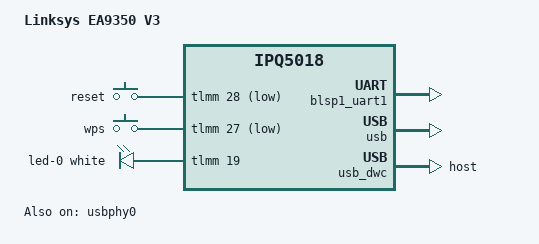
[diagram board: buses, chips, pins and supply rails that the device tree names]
// SPDX-License-Identifier: GPL-2.0+ OR BSD-3-Clause

/dts-v1/;

/*
 * NOTE: The original firmware from Linksys can only boot ARM32 kernels.
 *
 * As of now There seems to be no way to boot ARM64 kernels on those device.
 *
 * However, it is possible to use this device tree by compiling an ARM32 kernel
 * instead. For clarity and build testing this device tree is maintained next
 * to the other IPQ5018 device trees. However, it is actually used through
 * arch/arm/boot/dts/qcom/qcom-ipq5018-linksys-jamaica.dts
 */

#include "ipq5018.dtsi"
#include <dt-bindings/input/input.h>
#include <dt-bindings/leds/common.h>
#include <dt-bindings/gpio/gpio.h>


/ {
	model = "Linksys EA9350 V3";
	compatible = "linksys,jamaica", "qcom,ipq5018";

	aliases {
		serial0 = &blsp1_uart1;
	};

	chosen {
		stdout-path = "serial0:115200n8";
	};

	gpio-keys {
		compatible = "gpio-keys";
		pinctrl-0 = <&button_pins>;
		pinctrl-names = "default";

		button-0 {
			label = "reset";
			linux,code = <KEY_RESTART>;
			gpios = <&tlmm 28 GPIO_ACTIVE_LOW>;
			debounce-interval = <60>;
		};

		button-1 {
			label = "wps";
			linux,code = <KEY_WPS_BUTTON>;
			gpios = <&tlmm 27 GPIO_ACTIVE_LOW>;
			debounce-interval = <60>;
		};
	};

	leds {
		compatible = "gpio-leds";
		pinctrl-0 = <&led_pins>;
		pinctrl-names = "default";

		led-0 {
			color = <LED_COLOR_ID_WHITE>;
			function = LED_FUNCTION_USB;
			gpios = <&tlmm 19 GPIO_ACTIVE_HIGH>;
		};
	};
};

&blsp1_uart1 {
	pinctrl-0 = <&uart1_pins>;
	pinctrl-names = "default";
	status = "okay";
};

&sleep_clk {
	clock-frequency = <32000>;
};

&tlmm {
	button_pins: button-pins-state {
		pins = "gpio27", "gpio28";
		function = "gpio";
		drive-strength = <8>;
		bias-pull-up;
	};

	led_pins: led-pins-state {
		pins = "gpio19";
		function = "gpio";
		drive-strength = <2>;
		bias-disable;
	};
};

&usb {
	status = "okay";
};

&usb_dwc {
	dr_mode = "host";
};

&usbphy0 {
	status = "okay";
};

&xo_board_clk {
	clock-frequency = <24000000>;
};
